# F28x7x_cputimer_regs register map
Vendor: Texas Instruments
Peripheral module from a debugger description file (folder C2000).
Address unit: 16 bits
Registers are 16-bit, read-write, no defined reset value unless marked. A register's access mark holds for its fields unless they carry their own. Offsets are as the file gives them; lines under a group give offsets from that group; [hi:lo] are bit positions; {n}, {i} and the like mark numbered series; 'fields as' and 'values as' point back to an identical list; <NAME> marks a mode.

## CPUTIMER_REGS — CPUTIMER Registers
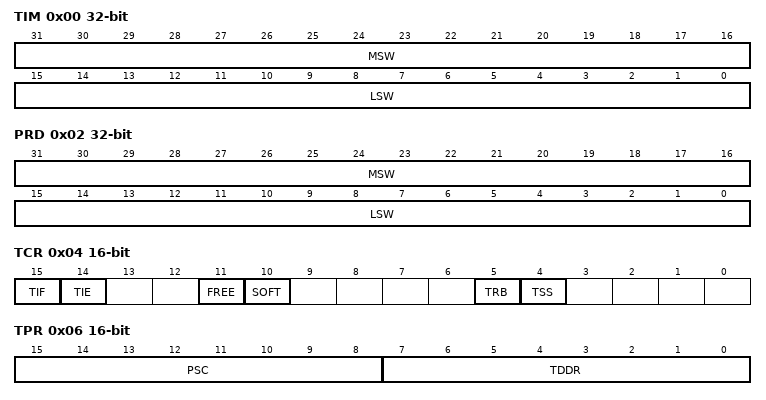
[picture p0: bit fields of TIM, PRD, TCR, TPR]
0x00 TIM 32-bit — CPU-Timer, Counter Register
  [31:16] MSW — CPU-Timer Counter Registers High
  [15:0] LSW — CPU-Timer Counter Registers
0x02 PRD 32-bit — CPU-Timer, Period Register
  [31:16] MSW — CPU-Timer Period Registers High
  [15:0] LSW — CPU-Timer Period Registers
0x04 TCR access not given — CPU-Timer, Control Register
  [15] TIF — CPU-Timer Interrupt Flag. (access R/W1toClr)
  [14] TIE rw — CPU-Timer Interrupt Enable.
  [11] FREE rw — Emulation modes
  [10] SOFT rw — Emulation modes
  [5] TRB rw — Timer reload
  [4] TSS rw — CPU-Timer stop status bit.
0x06 TPR access per field — CPU-Timer, Prescale Register
  [15:8] PSC ro — CPU-Timer Prescale Counter.
  [7:0] TDDR rw — CPU-Timer Divide-Down.
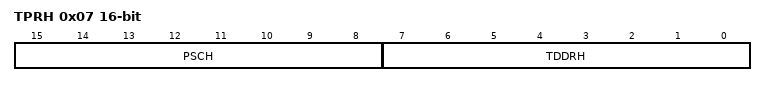
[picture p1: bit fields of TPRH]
0x07 TPRH access per field — CPU-Timer, Prescale Register High
  [15:8] PSCH ro — CPU-Timer Prescale Counter.
  [7:0] TDDRH rw — CPU-Timer Divide-Down.
